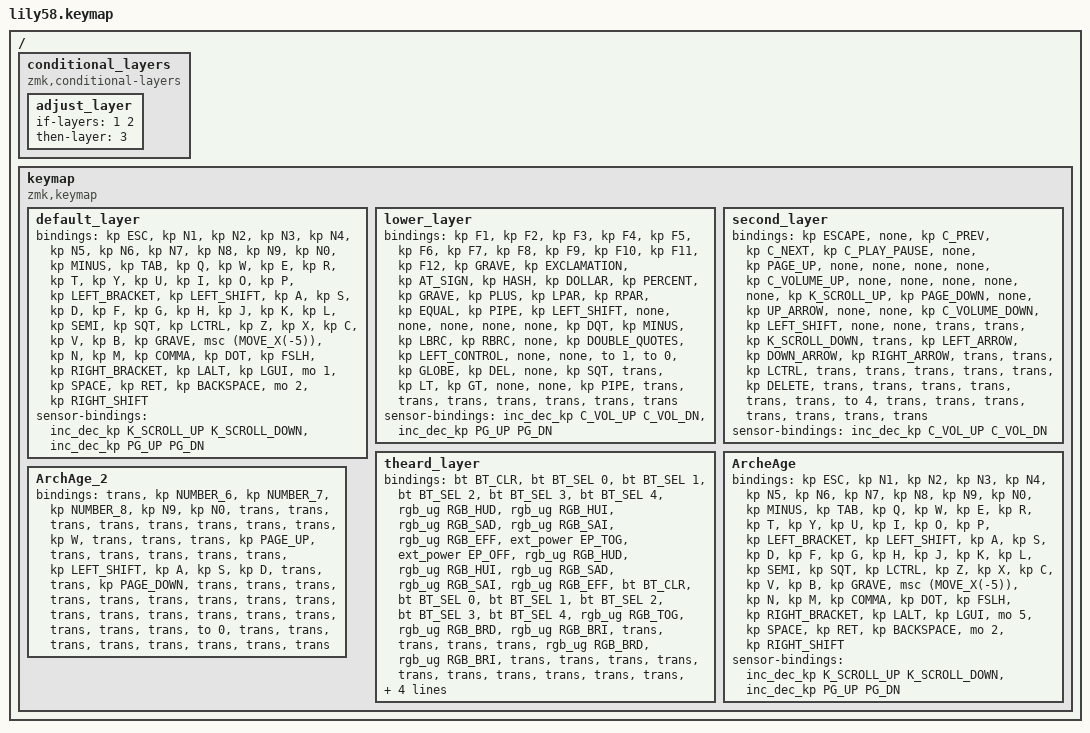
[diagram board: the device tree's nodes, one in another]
/*
 * Copyright (c) 2020 The ZMK Contributors
 *
 * SPDX-License-Identifier: MIT
 */

#include <behaviors.dtsi>
#include <dt-bindings/zmk/bt.h>
#include <dt-bindings/zmk/ext_power.h>
#include <dt-bindings/zmk/keys.h>
#include <dt-bindings/zmk/pointing.h>
#include <dt-bindings/zmk/rgb.h>

/ {
    // Activate ADJUST layer by pressing raise and lower

    conditional_layers {
        compatible = "zmk,conditional-layers";

        adjust_layer {
            if-layers = <1 2>;
            then-layer = <3>;
        };
    };

    keymap {
        compatible = "zmk,keymap";

        default_layer {
            bindings = <
&kp ESC         &kp N1  &kp N2  &kp N3    &kp N4    &kp N5                                  &kp N6         &kp N7  &kp N8           &kp N9   &kp N0    &kp MINUS
&kp TAB         &kp Q   &kp W   &kp E     &kp R     &kp T                                   &kp Y          &kp U   &kp I            &kp O    &kp P     &kp LEFT_BRACKET
&kp LEFT_SHIFT  &kp A   &kp S   &kp D     &kp F     &kp G                                   &kp H          &kp J   &kp K            &kp L    &kp SEMI  &kp SQT
&kp LCTRL       &kp Z   &kp X   &kp C     &kp V     &kp B   &kp GRAVE    &msc (MOVE_X(-5))  &kp N          &kp M   &kp COMMA        &kp DOT  &kp FSLH  &kp RIGHT_BRACKET
                                &kp LALT  &kp LGUI  &mo 1   &kp SPACE    &kp RET            &kp BACKSPACE  &mo 2   &kp RIGHT_SHIFT
            >;

            sensor-bindings =
                <&inc_dec_kp K_SCROLL_UP K_SCROLL_DOWN>,
                <&inc_dec_kp PG_UP PG_DN>;
        };

        lower_layer {
            bindings = <
&kp F1            &kp F2           &kp F3       &kp F4    &kp F5      &kp F6                          &kp F7     &kp F8     &kp F9    &kp F10   &kp F11    &kp F12
&kp GRAVE         &kp EXCLAMATION  &kp AT_SIGN  &kp HASH  &kp DOLLAR  &kp PERCENT                     &kp GRAVE  &kp PLUS   &kp LPAR  &kp RPAR  &kp EQUAL  &kp PIPE
&kp LEFT_SHIFT    &none            &none        &none     &none       &none                           &kp DQT    &kp MINUS  &kp LBRC  &kp RBRC  &none      &kp DOUBLE_QUOTES
&kp LEFT_CONTROL  &none            &none        &to 1     &to 0       &kp GLOBE    &kp DEL    &none   &kp SQT    &trans     &kp LT    &kp GT    &none      &none
                                                &kp PIPE  &trans      &trans       &trans     &trans  &trans     &trans     &trans
            >;

            sensor-bindings = <&inc_dec_kp C_VOL_UP C_VOL_DN &inc_dec_kp PG_UP PG_DN>;
        };

        second_layer {
            bindings = <
&kp ESCAPE      &none   &kp C_PREV  &kp C_NEXT  &kp C_PLAY_PAUSE  &none                                    &kp PAGE_UP    &none           &none           &none            &none   &kp C_VOLUME_UP
&none           &none   &none       &none       &none             &kp K_SCROLL_UP                          &kp PAGE_DOWN  &none           &kp UP_ARROW    &none            &none   &kp C_VOLUME_DOWN
&kp LEFT_SHIFT  &none   &none       &trans      &trans            &kp K_SCROLL_DOWN                        &trans         &kp LEFT_ARROW  &kp DOWN_ARROW  &kp RIGHT_ARROW  &trans  &trans
&kp LCTRL       &trans  &trans      &trans      &trans            &trans             &kp DELETE    &trans  &trans         &trans          &trans          &trans           &trans  &to 4
                                    &trans      &trans            &trans             &trans        &trans  &trans         &trans
            >;

            sensor-bindings = <&inc_dec_kp C_VOL_UP C_VOL_DN>;
        };

        theard_layer {
            bindings = <
&bt BT_CLR         &bt BT_SEL 0     &bt BT_SEL 1     &bt BT_SEL 2     &bt BT_SEL 3     &bt BT_SEL 4                       &rgb_ug RGB_HUD  &rgb_ug RGB_HUI  &rgb_ug RGB_SAD  &rgb_ug RGB_SAI  &rgb_ug RGB_EFF  &ext_power EP_TOG
&ext_power EP_OFF  &rgb_ug RGB_HUD  &rgb_ug RGB_HUI  &rgb_ug RGB_SAD  &rgb_ug RGB_SAI  &rgb_ug RGB_EFF                    &bt BT_CLR       &bt BT_SEL 0     &bt BT_SEL 1     &bt BT_SEL 2     &bt BT_SEL 3     &bt BT_SEL 4
&rgb_ug RGB_TOG    &rgb_ug RGB_BRD  &rgb_ug RGB_BRI  &trans           &trans           &trans                             &trans           &rgb_ug RGB_BRD  &rgb_ug RGB_BRI  &trans           &trans           &trans
&trans             &trans           &trans           &trans           &trans           &trans           &trans    &trans  &trans           &trans           &trans           &trans           &trans           &trans
                                                     &trans           &trans           &trans           &trans    &trans  &trans           &trans
            >;

            sensor-bindings = <&inc_dec_kp C_VOL_UP C_VOL_DN>;
        };

        ArcheAge {
            bindings = <
&kp ESC         &kp N1  &kp N2  &kp N3    &kp N4    &kp N5                                  &kp N6         &kp N7  &kp N8           &kp N9   &kp N0    &kp MINUS
&kp TAB         &kp Q   &kp W   &kp E     &kp R     &kp T                                   &kp Y          &kp U   &kp I            &kp O    &kp P     &kp LEFT_BRACKET
&kp LEFT_SHIFT  &kp A   &kp S   &kp D     &kp F     &kp G                                   &kp H          &kp J   &kp K            &kp L    &kp SEMI  &kp SQT
&kp LCTRL       &kp Z   &kp X   &kp C     &kp V     &kp B   &kp GRAVE    &msc (MOVE_X(-5))  &kp N          &kp M   &kp COMMA        &kp DOT  &kp FSLH  &kp RIGHT_BRACKET
                                &kp LALT  &kp LGUI  &mo 5   &kp SPACE    &kp RET            &kp BACKSPACE  &mo 2   &kp RIGHT_SHIFT
            >;

            sensor-bindings =
                <&inc_dec_kp K_SCROLL_UP K_SCROLL_DOWN>,
                <&inc_dec_kp PG_UP PG_DN>;
        };

        ArchAge_2 {
            bindings = <
&trans          &kp NUMBER_6  &kp NUMBER_7  &kp NUMBER_8  &kp N9  &kp N0                    &trans         &trans  &trans  &trans  &trans  &trans
&trans          &trans        &kp W         &trans        &trans  &trans                    &kp PAGE_UP    &trans  &trans  &trans  &trans  &trans
&kp LEFT_SHIFT  &kp A         &kp S         &kp D         &trans  &trans                    &kp PAGE_DOWN  &trans  &trans  &trans  &trans  &trans
&trans          &trans        &trans        &trans        &trans  &trans  &trans    &trans  &trans         &trans  &trans  &trans  &trans  &to 0
                                            &trans        &trans  &trans  &trans    &trans  &trans         &trans  &trans
            >;
        };
    };
};
